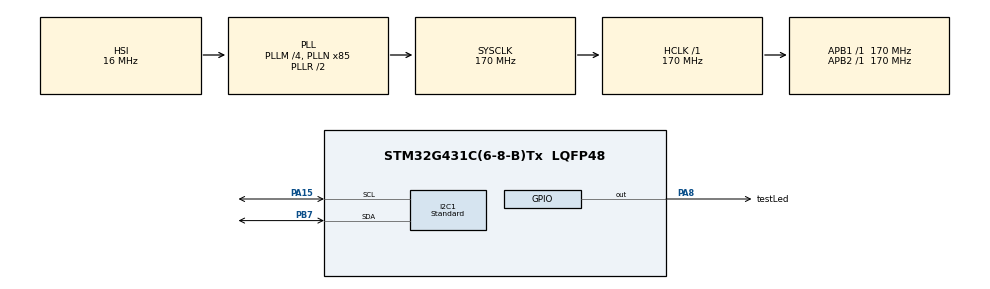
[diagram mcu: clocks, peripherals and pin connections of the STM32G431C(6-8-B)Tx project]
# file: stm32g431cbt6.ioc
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I2C1.Analog_Filter=I2C_ANALOGFILTER_DISABLE
I2C1.I2C_Speed_Mode=I2C_Standard
I2C1.Timing=0x509170A3
Mcu.Family=STM32G4
Mcu.Name=STM32G431C(6-8-B)Tx
Mcu.Package=LQFP48
NVIC.PriorityGroup=NVIC_PRIORITYGROUP_4
PA13.Mode=Serial_Wire
PA13.Signal=SYS_JTMS-SWDIO
PA14.Mode=Serial_Wire
PA14.Signal=SYS_JTCK-SWCLK
PA15.Mode=I2C
PA15.Signal=I2C1_SCL
PA8.GPIO_Label=testLed
PA8.Signal=GPIO_Output
PB7.Mode=I2C
PB7.Signal=I2C1_SDA
ProjectManager.HeapSize=0x200
ProjectManager.StackSize=0x400
ProjectManager.TargetToolchain=STM32CubeIDE
RCC.ADC12Freq_Value=170000000
RCC.AHBFreq_Value=170000000
RCC.APB1Freq_Value=170000000
RCC.APB1TimFreq_Value=170000000
RCC.APB2Freq_Value=170000000
RCC.APB2TimFreq_Value=170000000
RCC.CortexFreq_Value=170000000
RCC.EXTERNAL_CLOCK_VALUE=12288000
RCC.HCLKFreq_Value=170000000
RCC.HSE_VALUE=8000000
RCC.HSI48_VALUE=48000000
RCC.HSI_VALUE=16000000
RCC.LSE_VALUE=32768
RCC.PLLM=RCC_PLLM_DIV4
RCC.PLLN=85
RCC.SYSCLKFreq_VALUE=170000000
RCC.SYSCLKSource=RCC_SYSCLKSOURCE_PLLCLK
RCC.USBFreq_Value=170000000
RCC.VCOOutputFreq_Value=340000000
VP_SYS_VS_DBSignals.Mode=DisableDeadBatterySignals
board=custom

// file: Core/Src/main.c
/* USER CODE BEGIN Header */
/**
 ******************************************************************************
 * @file           : main.c
 * @brief          : Main program body
 ******************************************************************************
 * @attention
 *
 * Copyright (c) 2026 STMicroelectronics.
 * All rights reserved.
 *
 * This software is licensed under terms that can be found in the LICENSE file
 * in the root directory of this software component.
 * If no LICENSE file comes with this software, it is provided AS-IS.
 *
 ******************************************************************************
 */
/* USER CODE END Header */
#include "main.h"
#include "i2c.h"
#include "gpio.h"

/* USER CODE BEGIN Includes */
#include "../../Drivers/MPU6050/mpu6050.h"
/* USER CODE END Includes */

/* USER CODE BEGIN PV */
SensorData_t mpu = { 0 };

uint8_t mpu_id = 0;

sensor_status_e mpu_status;

volatile uint8_t debug_id = 0xFF;
volatile HAL_StatusTypeDef debug_ready;
volatile HAL_StatusTypeDef debug_read;
volatile uint32_t debug_error;

volatile int32_t accX_debug;
volatile int32_t accY_debug;
volatile int32_t accZ_debug;
volatile int32_t temp_debug;
/* USER CODE END PV */

void SystemClock_Config(void);

int main(void) {

	/* MCU Configuration--------------------------------------------------------*/

	/* Reset of all peripherals, Initializes the Flash interface and the Systick. */
 	HAL_Init();

	/* Configure the system clock */
	SystemClock_Config();

	/* Initialize all configured peripherals */
	MX_GPIO_Init();
	MX_I2C1_Init();
	/* USER CODE BEGIN 2 */

	uint8_t rx = 0xFF;

	// Check sensor ACK
	debug_ready = HAL_I2C_IsDeviceReady(&hi2c1, 0x68U << 1, 3, 100);

	// Read WHO_AM_I register (0x75)
	debug_read = HAL_I2C_Mem_Read(&hi2c1, 0x68U << 1, 0x75,
	I2C_MEMADD_SIZE_8BIT, &rx, 1, 100);

	debug_id = rx;
	debug_error = HAL_I2C_GetError(&hi2c1);

	mpu_id = MPU6050_READ_ID(&hi2c1);

	if (MPU6050_Init(&hi2c1) == 0U) {
		mpu_status = MPU6050_initialize(&mpu, FS_250, AFS_2G);
	} else {
		mpu_status = SENSOR_ERROR;
	}

	/* USER CODE END 2 */

	/* Infinite loop */
	while (1) {

		/* USER CODE BEGIN 3 */
		if (MPU6050_read_data(&mpu) == SENSOR_OK)
		{
		    accX_debug = (int32_t)(mpu.acc.X * 1000.0);
		    accY_debug = (int32_t)(mpu.acc.Y * 1000.0);
		    accZ_debug = (int32_t)(mpu.acc.Z * 1000.0);

		    temp_debug = (int32_t)(mpu.temperatureC * 100.0);
		}

		HAL_Delay(100);

	}
	/* USER CODE END 3 */
}

void SystemClock_Config(void) {
	RCC_OscInitTypeDef RCC_OscInitStruct = { 0 };
	RCC_ClkInitTypeDef RCC_ClkInitStruct = { 0 };

	/** Configure the main internal regulator output voltage
	 */
	HAL_PWREx_ControlVoltageScaling(PWR_REGULATOR_VOLTAGE_SCALE1_BOOST);

	/** Initializes the RCC Oscillators according to the specified parameters
	 * in the RCC_OscInitTypeDef structure.
	 */
	RCC_OscInitStruct.OscillatorType = RCC_OSCILLATORTYPE_HSI;
	RCC_OscInitStruct.HSIState = RCC_HSI_ON;
	RCC_OscInitStruct.HSICalibrationValue = RCC_HSICALIBRATION_DEFAULT;
	RCC_OscInitStruct.PLL.PLLState = RCC_PLL_ON;
	RCC_OscInitStruct.PLL.PLLSource = RCC_PLLSOURCE_HSI;
	RCC_OscInitStruct.PLL.PLLM = RCC_PLLM_DIV4;
	RCC_OscInitStruct.PLL.PLLN = 85;
	RCC_OscInitStruct.PLL.PLLP = RCC_PLLP_DIV2;
	RCC_OscInitStruct.PLL.PLLQ = RCC_PLLQ_DIV2;
	RCC_OscInitStruct.PLL.PLLR = RCC_PLLR_DIV2;
	if (HAL_RCC_OscConfig(&RCC_OscInitStruct) != HAL_OK) {
		Error_Handler();
	}

	/** Initializes the CPU, AHB and APB buses clocks
	 */
	RCC_ClkInitStruct.ClockType = RCC_CLOCKTYPE_HCLK | RCC_CLOCKTYPE_SYSCLK
			| RCC_CLOCKTYPE_PCLK1 | RCC_CLOCKTYPE_PCLK2;
	RCC_ClkInitStruct.SYSCLKSource = RCC_SYSCLKSOURCE_PLLCLK;
	RCC_ClkInitStruct.AHBCLKDivider = RCC_SYSCLK_DIV1;
	RCC_ClkInitStruct.APB1CLKDivider = RCC_HCLK_DIV1;
	RCC_ClkInitStruct.APB2CLKDivider = RCC_HCLK_DIV1;

	if (HAL_RCC_ClockConfig(&RCC_ClkInitStruct, FLASH_LATENCY_4) != HAL_OK) {
		Error_Handler();
	}
}

void Error_Handler(void) {
	__disable_irq();
	while (1) {
	}
}
